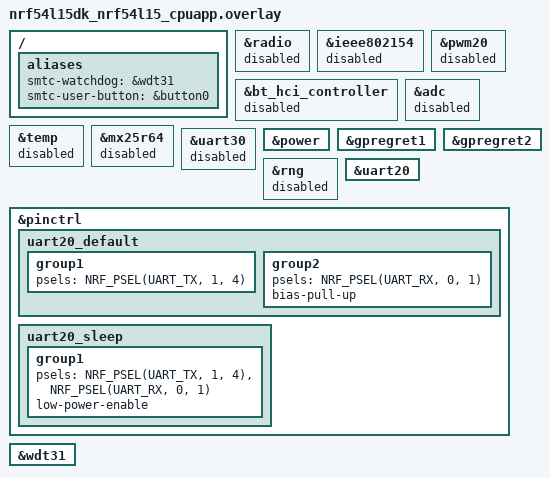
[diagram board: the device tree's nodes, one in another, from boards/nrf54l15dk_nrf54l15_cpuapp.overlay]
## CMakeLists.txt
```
# Copyright (c) 2024 Semtech Corporation
# SPDX-License-Identifier: Apache-2.0

cmake_minimum_required(VERSION 3.13.1)

find_package(Zephyr REQUIRED HINTS $ENV{ZEPHYR_BASE})
project(direct_driver_access)

target_sources(app PRIVATE
  ${CMAKE_CURRENT_SOURCE_DIR}/src/main.c
  ${ZEPHYR_USP_MODULE_DIR}/examples/main_examples/direct_driver_access_example/app_direct_driver_access.c
)

zephyr_include_directories(
  ${ZEPHYR_USP_MODULE_DIR}/examples/main_examples/direct_driver_access_example
)
```

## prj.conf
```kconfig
# Copyright (c) 2024 Semtech Corporation
# SPDX-License-Identifier: Apache-2.0

# --------------------------- General configuration ---------------------------

CONFIG_USE_SEGGER_RTT=n

# heap size
CONFIG_HEAP_MEM_POOL_SIZE=4096

CONFIG_LOG=y

CONFIG_TEST_RANDOM_GENERATOR=y

CONFIG_PM_DEVICE=y

CONFIG_WATCHDOG=n

CONFIG_FLASH=y

# ------------------------------ Transceiver driver ----------------------------

CONFIG_LORA_BASICS_MODEM_DRIVERS=y
# We chose to disable intermediate thread between IRQ and USP RAC Thread to make timestamping is as fast as possible
CONFIG_LORA_BASICS_MODEM_DRIVERS_EVENT_TRIGGER_NO_THREAD=y
#CONFIG_LORA_BASICS_MODEM_DRIVERS_EVENT_TRIGGER_GLOBAL_THREAD=n
#CONFIG_LORA_BASICS_MODEM_DRIVERS_EVENT_TRIGGER_OWN_THREAD=n

# ------------------------------ USP -----------------------------


CONFIG_USP=y
CONFIG_USP_MAIN_THREAD=y

#CONFIG_USP_LOG_LEVEL_DBG=y

CONFIG_LOG_BUFFER_SIZE=4096

# CONFIG_CLOCK_CONTROL=y
# CONFIG_CLOCK_CONTROL_NRF=y

CONFIG_MAIN_STACK_SIZE=4096
CONFIG_STACK_SENTINEL=y

# Debug stack (à enlever en production)
CONFIG_THREAD_STACK_INFO=y
CONFIG_STACK_SENTINEL=y
CONFIG_THREAD_MONITOR=y
CONFIG_THREAD_NAME=y

# Threads are cooperative (non-preemptive) to simplify critical section management and avoid complex synchronization.
# This approach may reduce reactivity when ISR (interrupt service routines) are triggered (low optimization)
# The USP RAC thread is assigned a higher priority: it will execute immediately once the Main thread yields or blocks, ensuring prompt handling of USP RAC-related tasks.
# The Main thread has a lower priority: it runs only when the USP RAC thread is idle or waiting
CONFIG_MAIN_THREAD_PRIORITY=-2
CONFIG_USP_MAIN_THREAD_PRIORITY=-4

# Threads are preemptive: a thread with a higher priority can interrupt (preempt) a lower priority thread at any time.
# USP RAC thread has higher priority (1): it will preempt the main thread immediately whenever it is ready to run (ISR/Timer), ensuring low latency and fast response for USP RAC-related tasks.
# Main thread has lower priority (3): it runs only when the USP RAC thread is not active, yielding CPU time to the more urgent USP RAC operations automatically.
# This priority scheme allows responsive multitasking with guaranteed preemption based on thread priority.
# CONFIG_MAIN_THREAD_PRIORITY=3
# CONFIG_USP_MAIN_THREAD_PRIORITY=1
# CONFIG_USP_THREADS_MUTEXES=y

#
# Priority Inversion : In case of multiple threads with different priorities, consider the modification of existing priorities and mutex use, or use Zephyr capabilities :
# CONFIG_KERNEL_MEM_POOL=y
# CONFIG_MUTEX_PRIORITY_INHERITANCE=y
# CONFIG_PRIORITY_CEILING=y

# Only one thread
# CONFIG_USP_MAIN_THREAD_PRIORITY=0


# ------------------------------ Debug -----------------------------
CONFIG_DEBUG=y
CONFIG_NO_OPTIMIZATIONS=y
CONFIG_DEBUG_OPTIMIZATIONS=y
CONFIG_DEBUG_THREAD_INFO=y
CONFIG_DCACHE=n
```

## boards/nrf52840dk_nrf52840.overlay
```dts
/*
 * Copyright (c) 2024 Semtech Corporation
 *
 * SPDX-License-Identifier: Apache-2.0
 */



/ {
	aliases {
		smtc-watchdog = &wdt;
		smtc-user-button = &button0;
	};
};

&spi1 {
	status = "disabled";
};

&spi2 {
	status = "disabled";
};

&qspi {
	status = "disabled";
};

&wdt {
	status = "okay";
};

&arduino_i2c {
        /delete-property/ zephyr,concat-buf-size;
};
```

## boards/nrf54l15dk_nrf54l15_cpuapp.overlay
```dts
// /*
//  * Copyright (c) 2024 Semtech Corporation
//  *
//  * SPDX-License-Identifier: Apache-2.0
//  */



/ {
	aliases {
		smtc-watchdog = &wdt31;
		smtc-user-button = &button0;
	};
};

&radio {
	status = "disabled";
};

&ieee802154 {
	status = "disabled";
};

&bt_hci_controller {
	status = "disabled";
};

&pwm20 {
	status = "disabled";
};

&adc {
	status = "disabled";
};

&temp {
	status = "disabled";
};

&mx25r64 {
	status = "disabled";
};


// &rng_hci {
	//     status = "disabled";
// };

&uart30 {
	status = "disabled";
};

// &clock {
	//     status = "disabled"; //For some reason, disabling it increases power consumption
// };

&power {
	status = "okay";
};

&gpregret1 {
	status = "okay";
};

&gpregret2 {
	status = "okay";
};

&rng {
	status = "disabled";
};

// &spi00 {
	//     status = "disabled";
// };


&uart20 {
	status = "okay";
	// disable-rx; //Disabling RX allows a gain of ~200µA, totally disabling uart allows another gain of ~200µA
	// /delete-property/ hw-flow-control;
};

&pinctrl {
	uart20_default: uart20_default {
		group1 {
			psels = <NRF_PSEL(UART_TX, 1, 4)>
			// ,<NRF_PSEL(UART_RTS, 0, 2)>
			;
		};
		group2 {
			psels = <NRF_PSEL(UART_RX, 0, 1)> //DIO9 is mapped on RX
			// ,<NRF_PSEL(UART_CTS, 0, 3)>
			;
			bias-pull-up;
		};
	};

	uart20_sleep: uart20_sleep {
		group1 {
			psels = <NRF_PSEL(UART_TX, 1, 4)>,
					<NRF_PSEL(UART_RX, 0, 1)>
					// ,<NRF_PSEL(UART_RTS, 0, 2)>
					// ,<NRF_PSEL(UART_CTS, 0, 3)>
					;
			low-power-enable;
		};
	};
};

&wdt31 {
	status = "okay";
};
```

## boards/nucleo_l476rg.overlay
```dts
/*
 * Copyright (c) 2024 Semtech Corporation
 *
 * SPDX-License-Identifier: Apache-2.0
 */

#include "user_keys.overlay"

/ {
	aliases {
		smtc-watchdog = &iwdg;
		smtc-user-button = &user_button;
	};
};

&spi3 {
	status = "disabled";
};

&iwdg {
	status = "disabled";
};

&arduino_spi {
	/delete-property/ overrun-character;
};
```

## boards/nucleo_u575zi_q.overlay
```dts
/*
 * Copyright (c) 2024 Semtech Corporation
 *
 * SPDX-License-Identifier: Apache-2.0
 */



/ {
	aliases {
		smtc-watchdog = &iwdg;
		smtc-user-button = &user_button;
	};
};

// Add user storage partition (not present in default nucleo_u575zi_q dts, as opposed to other boards)
&flash0 {
	partitions {
		compatible = "fixed-partitions";
		#address-cells = < 0x1 >;
		#size-cells = < 0x1 >;

		storage_partition: partition@1f8000 {
			label = "storage";
			reg = < 0x1f8000 0x8000 >;
		};
	};
};


&i2c1 {
	status = "disabled";
};

&i2c2 {
	status = "disabled";
};

&lptim1 {
	status = "disabled";
};

&timers3 {
	status = "disabled";
};

&timers4 {
	status = "disabled";
};

&dac1 {
	status = "disabled";
};

&adc1 {
	status = "disabled";
};

&adc4 {
	status = "disabled";
};

&fdcan1 {
	status = "disabled";
};

&usbotg_fs {
	status = "disabled";
};

&usart2 {
	status = "disabled";
};

&iwdg {
	status = "disabled";
};

&wwdg {
	status = "disabled";
};

&arduino_i2c {
        /delete-property/ zephyr,concat-buf-size;
};

&arduino_spi {
	/delete-property/ overrun-character;
};
```

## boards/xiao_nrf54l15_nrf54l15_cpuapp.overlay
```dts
// /*
//  * Copyright (c) 2024 Semtech Corporation
//  *
//  * SPDX-License-Identifier: Apache-2.0
//  */



/ {
	aliases {
		smtc-watchdog = &wdt31;
		smtc-user-button = &usr_btn;
	};
};

&xiao_serial {
	status = "disabled";
};

&i2c22 {
	status = "okay";
};

&i2c30 {
	status = "disabled";
};

&adc {
	status = "disabled";
};

&wdt31 {
	status = "okay";
};

// Override xiao_nrf54l15 default configuration for USP applications
// Disable boot-on for RF switch regulators to save power

&rfsw_ctl {
	/delete-property/ regulator-boot-on;
};

&rfsw_pwr {
	/delete-property/ regulator-boot-on;
};

&vbat_pwr {
	/delete-property/ regulator-boot-on;
};
```

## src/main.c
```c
/**
 * @file      main.c
 *
 * @brief     Application main
 *
 * The Clear BSD License
 * Copyright Semtech Corporation 2025. All rights reserved.
 *
 * Redistribution and use in source and binary forms, with or without
 * modification, are permitted (subject to the limitations in the disclaimer
 * below) provided that the following conditions are met:
 *     * Redistributions of source code must retain the above copyright
 *       notice, this list of conditions and the following disclaimer.
 *     * Redistributions in binary form must reproduce the above copyright
 *       notice, this list of conditions and the following disclaimer in the
 *       documentation and/or other materials provided with the distribution.
 *     * Neither the name of the Semtech corporation nor the
 *       names of its contributors may be used to endorse or promote products
 *       derived from this software without specific prior written permission.
 *
 * NO EXPRESS OR IMPLIED LICENSES TO ANY PARTY'S PATENT RIGHTS ARE GRANTED BY
 * THIS LICENSE. THIS SOFTWARE IS PROVIDED BY THE COPYRIGHT HOLDERS AND
 * CONTRIBUTORS "AS IS" AND ANY EXPRESS OR IMPLIED WARRANTIES, INCLUDING, BUT
 * NOT LIMITED TO, THE IMPLIED WARRANTIES OF MERCHANTABILITY AND FITNESS FOR A
 * PARTICULAR PURPOSE ARE DISCLAIMED. IN NO EVENT SHALL SEMTECH CORPORATION BE
 * LIABLE FOR ANY DIRECT, INDIRECT, INCIDENTAL, SPECIAL, EXEMPLARY, OR
 * CONSEQUENTIAL DAMAGES (INCLUDING, BUT NOT LIMITED TO, PROCUREMENT OF
 * SUBSTITUTE GOODS OR SERVICES; LOSS OF USE, DATA, OR PROFITS; OR BUSINESS
 * INTERRUPTION) HOWEVER CAUSED AND ON ANY THEORY OF LIABILITY, WHETHER IN
 * CONTRACT, STRICT LIABILITY, OR TORT (INCLUDING NEGLIGENCE OR OTHERWISE)
 * ARISING IN ANY WAY OUT OF THE USE OF THIS SOFTWARE, EVEN IF ADVISED OF THE
 * POSSIBILITY OF SUCH DAMAGE.
 */

#include <stdint.h>   // C99 types
#include <stdbool.h>  // bool type

#include <zephyr/kernel.h>
#include <zephyr/drivers/gpio.h>

#include <zephyr/kernel.h>
#include <zephyr/drivers/gpio.h>
#include <zephyr/devicetree.h>
#include <zephyr/device.h>
#include <zephyr/logging/log.h>

#include "app_direct_driver_access.h"

#define SMTC_HAL_DBG_TRACE_C
#include <smtc_hal_dbg_trace.h>
#include <smtc_hal_led.h>
#include <smtc_zephyr_usp_api.h>
#include <smtc_sw_platform_helper.h>

#include <zephyr/lorawan_lbm/lorawan_hal_init.h>
#include <smtc_core_hal.h>

/*
 * -----------------------------------------------------------------------------
 * --- PRIVATE MACROS-----------------------------------------------------------
 */

LOG_MODULE_REGISTER( direct_driver_access, LOG_LEVEL_INF );

/*
 * -----------------------------------------------------------------------------
 * --- PRIVATE CONSTANTS -------------------------------------------------------
 */

/**
 * @brief Watchdog counter reload value during sleep (The period must be lower than MCU watchdog period (here 32s))
 */
#define WATCHDOG_RELOAD_PERIOD_MS 20000

/**
 * @brief Blue user button or BUTTON 1 on nrf52840-dk
 */

#define USER_BUTTON_NODE DT_ALIAS( smtc_user_button )
#if !DT_NODE_HAS_STATUS( USER_BUTTON_NODE, okay )
#error "Unsupported board: smtc-user-button devicetree alias is not defined"
#endif
static const struct gpio_dt_spec button = GPIO_DT_SPEC_GET_OR( USER_BUTTON_NODE, gpios, { 0 } );
static struct gpio_callback      button_cb_data;

/*
 * -----------------------------------------------------------------------------
 * --- PRIVATE TYPES -----------------------------------------------------------
 */
static volatile bool user_button_is_press = false;  // Flag for button status

/*
 * -----------------------------------------------------------------------------
 * --- PRIVATE VARIABLES -------------------------------------------------------
 */

/*
 * -----------------------------------------------------------------------------
 * --- PRIVATE FUNCTIONS DECLARATION -------------------------------------------
 * Prototypes for internal helper functions.
 */

/**
 * @brief User callback for button EXTI
 *
 * @param context Define by the user at the init
 */
static void user_button_callback( const void* context );

/**
 * @brief Configure User Button
 *
 */
static int configure_user_button( void );

/*
 * -----------------------------------------------------------------------------
 * --- PUBLIC FUNCTIONS DEFINITION ---------------------------------------------
 */

/* A binary semaphore to notify the main LBM loop */
K_SEM_DEFINE( periodical_uplink_event_sem, 0, 1 );

/* for zephyr compat*/
void button_pressed( const struct device* dev, struct gpio_callback* cb, uint32_t pins )
{
    printk( "%s", __func__ );
    user_button_callback( dev );
}

int main( void )
{
    if( configure_user_button( ) != 0 )
    {
        LOG_ERR( "Issue when configuring user button, aborting\n" );
        return 1;
    }

    SMTC_HAL_TRACE_INFO( "===== Direct Driver Access example =====\r\n" );

    SMTC_SW_PLATFORM_INIT( );
    SMTC_SW_PLATFORM_VOID( smtc_rac_init( ) );

    // initialize LEDs
    hal_led_init( );
    hal_led_set( HAL_LED_TX, false );
    hal_led_set( HAL_LED_RX, false );

    // initialize and start applications
    direct_driver_access_init( );

    // Main application loop
    while( true )
    {
        // Check button
        if( user_button_is_press == true )
        {
            user_button_is_press = false;

            direct_driver_access_on_button_press( );
        }

#if !defined( CONFIG_USP_MAIN_THREAD )
        smtc_rac_run_engine( );
        if( smtc_rac_is_irq_flag_pending( ) )
        {
            continue;
        }
        // Allows waking up on radio event or push-button press
        struct k_sem* sems[] = { smtc_modem_hal_get_event_sem( ), &periodical_uplink_event_sem };
        ( void ) wait_on_sems( sems, 2, K_MSEC( WATCHDOG_RELOAD_PERIOD_MS ) );
#else
        if( user_button_is_press == false )
        {
            k_sem_take( &periodical_uplink_event_sem, K_MSEC( WATCHDOG_RELOAD_PERIOD_MS ) );
        }
#endif
    }
    return 0;
}

/*
 * -----------------------------------------------------------------------------
 * --- PRIVATE FUNCTIONS DEFINITION --------------------------------------------
 */

static int configure_user_button( void )
{
    int ret = 0;
    if( !gpio_is_ready_dt( &button ) )
    {
        printk( "Error: button device %s is not ready\n", button.port->name );
        return 1;
    }

    ret = gpio_pin_configure_dt( &button, GPIO_INPUT );
    if( ret != 0 )
    {
        printk( "Error %d: failed to configure %s pin %d\n", ret, button.port->name, button.pin );
        return 1;
    }

    ret = gpio_pin_interrupt_configure_dt( &button, GPIO_INT_EDGE_TO_ACTIVE );
    if( ret != 0 )
    {
        printk( "Error %d: failed to configure interrupt on %s pin %d\n", ret, button.port->name, button.pin );
        return 1;
    }

    gpio_init_callback( &button_cb_data, button_pressed, BIT( button.pin ) );
    gpio_add_callback( button.port, &button_cb_data );

    return 0;
}

static void user_button_callback( const void* context )
{
    LOG_INF( "Button pushed\n" );

    ( void ) context;  // Not used in the example - avoid warning

    static uint32_t last_press_timestamp_ms = 0;

    // Debounce the button press, avoid multiple triggers
    if( ( int32_t ) ( smtc_modem_hal_get_time_in_ms( ) - last_press_timestamp_ms ) > 500 )
    {
        last_press_timestamp_ms = smtc_modem_hal_get_time_in_ms( );
        user_button_is_press    = true;
    }
    // Wake up the main thread
    k_sem_give( &periodical_uplink_event_sem );
}

/* --- EOF ------------------------------------------------------------------ */
```
